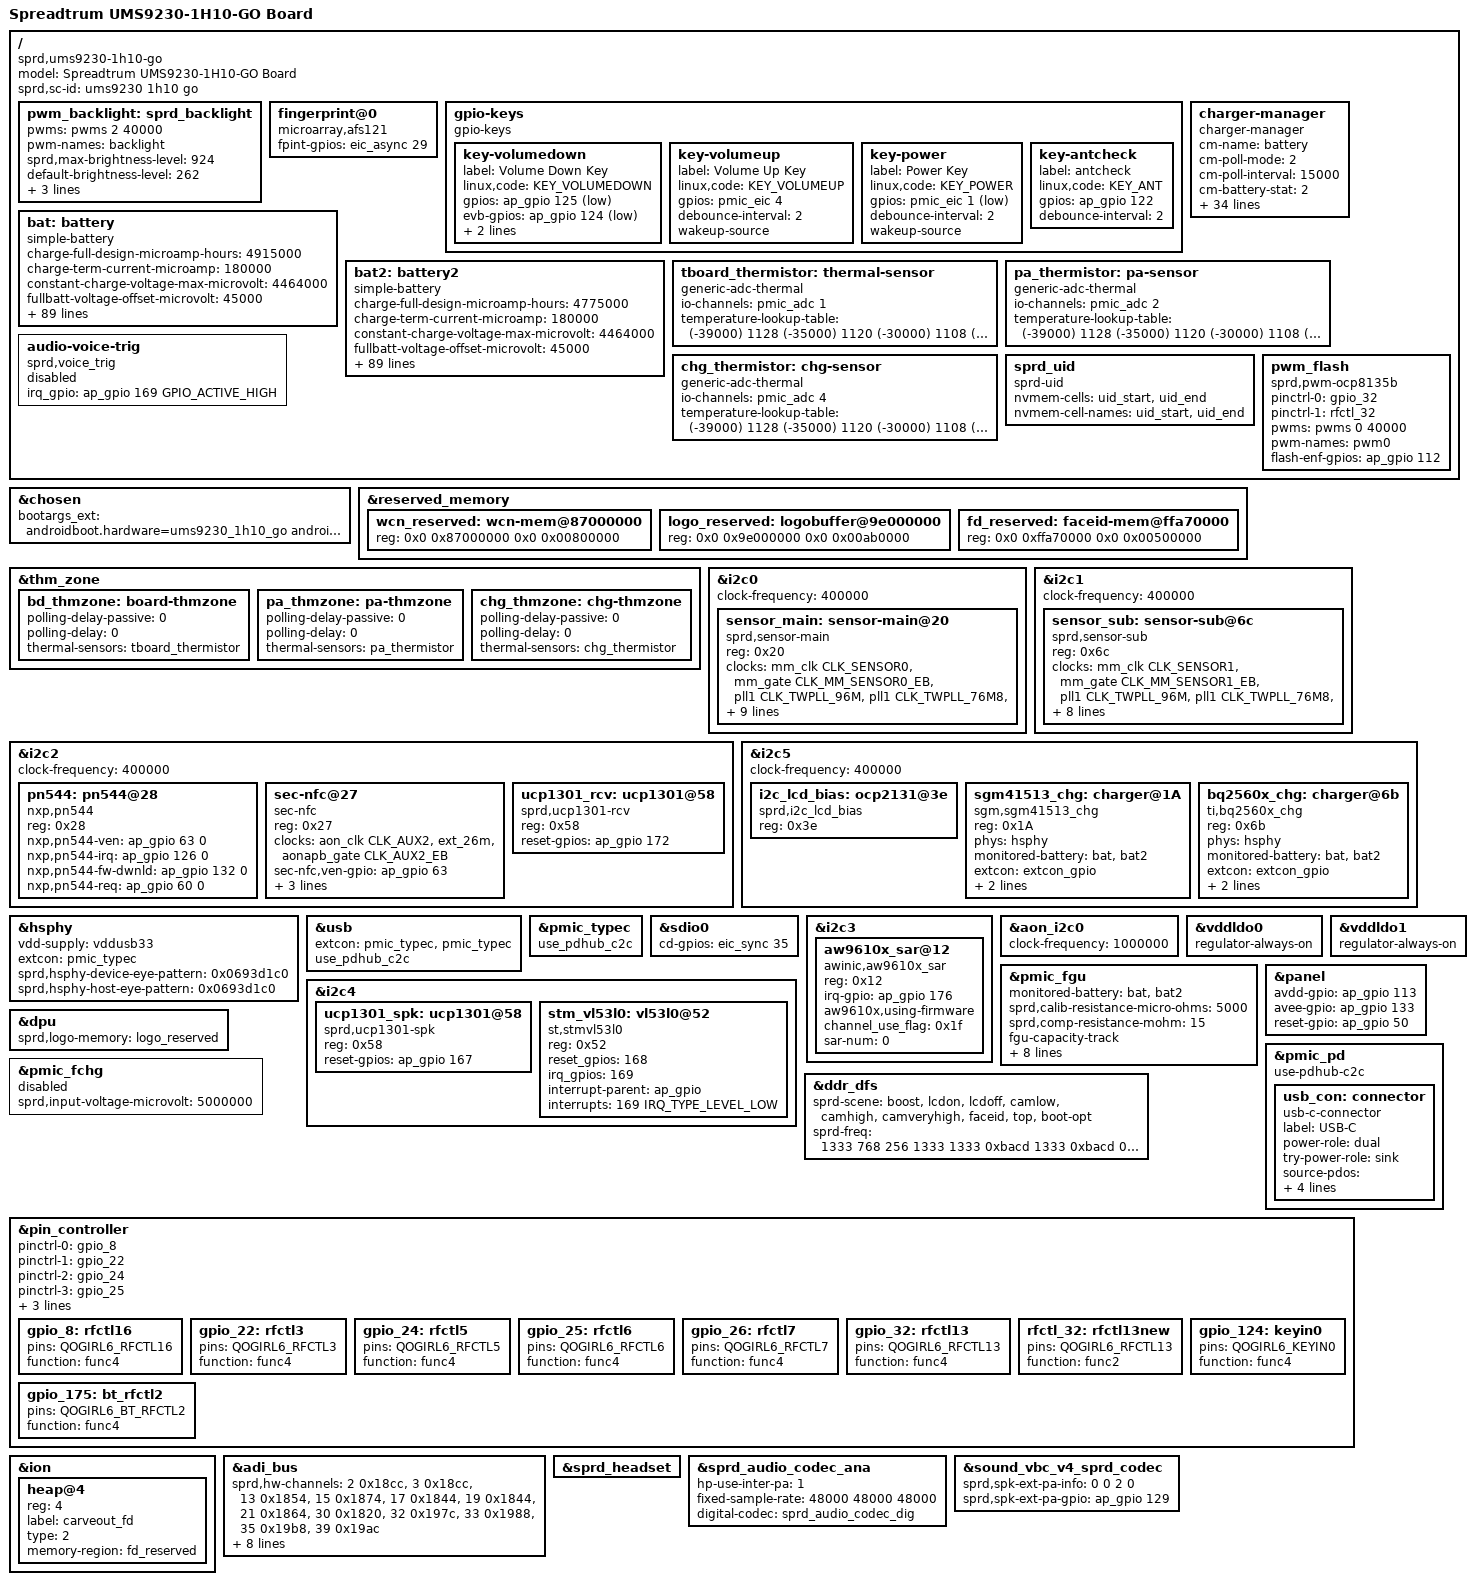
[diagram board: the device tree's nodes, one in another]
/dts-v1/;
/plugin/;
#include <dt-bindings/input/input.h>
#include <dt-bindings/gpio/gpio.h>
#include <dt-bindings/interrupt-controller/arm-gic.h>
#include <dt-bindings/clock/sprd,ums9230-clk.h>
#include <dt-bindings/mfd/sprd,sc2730-regs.h>
#include <dt-bindings/mfd/sprd,sc2730-mask.h>
#include <dt-bindings/usb/pd.h>
#include "lcd/lcd_ili9882q_boe_mipi_hd.dtsi"
#include "lcd/lcd_nt36528_tm_mipi_hd.dtsi"
#include "lcd/lcd_dummy_mipi.dtsi"
#include "tp/ums9230-spi3-gpio144-145-tp.dtsi"
#include "ums9230-wcn.dtsi"

/ {

	model = "Spreadtrum UMS9230-1H10-GO Board";

	compatible = "sprd,ums9230-1h10-go";

	sprd,sc-id = "ums9230 1h10 go";
	fragment {
		target-path = "/";
		__overlay__ {
			pwm_backlight: sprd_backlight {
				//compatible = "sprd,sharkl6-backlight";	//m170 use cabc_pwm, not pwm_backlight
				pwms = <&pwms 2 40000>;
				pwm-names = "backlight";
				sprd,max-brightness-level = <924>;
				default-brightness-level = <262>;
				sprd,brightness-scale = <1023>;
				brightness-levels = <
							  0   3   4   5   6   7
					  8   9  10  11  12  13  14  16  17  18
					 19  20  21  22  23  24  25  26  27  28
					 29  31  33  35  37  39  41  43  45  47
					 48  50  52  54  56  58  60  62  64  67
					 69  72  74  76  78  80  82  84  86  88
					 90  92  94  96  98 100 102 104 107 109
					112 114 116 118 120 122 124 126 128 130
					132 134 136 138 140 142 144 147 149 151
					154 156 158 160 162 164 166 168 170 172
					175 178 181 184 187 190 193 196 199 203
					205 208 211 214 217 220 223 226 229 234
					237 240 243 247 250 253 256 259 263 266
					269 270 274 277 280 283 287 290 294 297
					300 303 307 310 314 318 325 329 334 339
					340 343 347 350 354 358 365 369 374 380
					382 385 389 392 396 400 407 411 416 422
					426 430 434 438 442 446 452 457 460 464
					470 474 480 486 492 498 504 508 512 516
					522 527 532 536 540 545 550 555 561 568
					574 579 584 589 594 600 605 610 615 620
					625 630 635 641 647 652 657 662 667 673
					688 694 700 706 712 716 720 725 730 735
					740 746 752 758 764 770 776 782 790 798
					803 810 817 825 832 840 845 850 855 861
					866 872 878 884 890 896 903 911 918 924
				>;
			};

			fingerprint@0 {
				compatible = "microarray,afs121";
				fpint-gpios = <&eic_async 29 0>;
			};

			gpio-keys {
				compatible = "gpio-keys";

				key-volumedown {
					label = "Volume Down Key";
					linux,code = <KEY_VOLUMEDOWN>;
					gpios = <&ap_gpio 125 GPIO_ACTIVE_LOW>;
					evb-gpios = <&ap_gpio 124 GPIO_ACTIVE_LOW>;
					debounce-interval = <2>;
					wakeup-source;
				};

				key-volumeup {
					label = "Volume Up Key";
					linux,code = <KEY_VOLUMEUP>;
					gpios = <&pmic_eic 4 GPIO_ACTIVE_HIGH>;
					debounce-interval = <2>;
					wakeup-source;
				};

				key-power {
					label = "Power Key";
					linux,code = <KEY_POWER>;
					gpios = <&pmic_eic 1 GPIO_ACTIVE_LOW>;
					debounce-interval = <2>;
					wakeup-source;
				};

				key-antcheck {
					label = "antcheck";
					linux,code = <KEY_ANT>;
					gpios = <&ap_gpio 122 GPIO_ACTIVE_HIGH>;
					debounce-interval = <2>;
					//wakeup-source;
				};

			};

			bat: battery {
				compatible = "simple-battery";
				charge-full-design-microamp-hours = <4915000>;
				charge-term-current-microamp = <180000>;
				constant-charge-voltage-max-microvolt = <4464000>;
				fullbatt-voltage-offset-microvolt = <45000>;
				factory-internal-resistance-micro-ohms = <126000>;
				voltage-min-design-microvolt = <3450000>;
				fast-charge-threshold-microvolt = <4100000>;
				fullbatt-voltage = <4350000>;
				fullbatt-current = <242000>;
				first-fullbatt-current = <150000>;
				fullbatt-track-end-vol = <4295000>;
				fullbatt-track-end-cur = <130000>;
				first-calib-voltage = <3683000>;
				first-calib-capacity = <50>;
				//ir-us-upper-limit-microvolt = <4500000>;
				//ir-cv-offset-microvolt = <100000>;
				//ir-rc-micro-ohms = <20000>;

				ocv-capacity-celsius = <25>;
				ocv-capacity-table-0 = <4389000 100>, <4330000 95>, <4273000 90>,
							<4214000 85>, <4157000 80>, <4103000 75>,
							<4052000 70>, <4006000 65>, <3964000 60>,
							<3905000 55>, <3868000 50>, <3842000 45>,
							<3821000 40>, <3804000 35>, <3789000 30>,
							<3769000 25>, <3748000 20>, <3724000 15>,
							<3694000 10>, <3683000 5>, <3400000 0>;
				voltage-temp-table = <1491668 600>, <1404493 650>, <1307739 700>, <1203814 750>,
							<1095466 800>, <986112 850>, <878559 900>,
							  <775113 950>, <678461 1000>, <590240 1050>,
							  <510773 1100>, <440156 1150>, <378279 1200>,
							  <324561 1250>, <278079 1300>, <238260 1350>,
							  <204267 1400>, <175208 1450>, <150460 1500>,
							  <129410 1550>, <111497 1600>, <96484 1650>,
							<83711 1700>, <72772 1750>, <63423 1800>,
							<55444 1850>, <48599 1900>, <42668 1950>,
							<37552 2000>, <33167 2050>;
				capacity-temp-table = <45 99>, <25 100>, <10 99>, <0 92>, <(-10) 86>;
				resistance-temp-table = <45 83>, <25 100>, <10 155>, <0 929>, <(-10) 994>;

				/*battery-internal-resistance-celsius = <(-20)>, <(-10)>, <0>, <10>,
					<25>, <35>, <45>, <55>;
				battery-internal-resistance-table-0 = <1224>, <1224>, <1140>,
					<1084>, <1034>, <1001>, <994>, <992>, <992>, <992>,
					<996>, <1002>, <1010>, <1024>, <1045>, <1072>, <1180>,
					<1393>, <1756>, <2461>, <4272>;
				battery-internal-resistance-table-1 = <893>, <893>, <818>, <767>,
					<743>, <705>, <685>, <684>, <678>, <675>, <672>, <673>,
					<679>, <691>, <709>, <734>, <765>, <799>, <839>, <899>,
					<1092>;
				battery-internal-resistance-table-2 = <407>, <407>, <402>, <423>,
					<429>, <428>, <409>, <416>, <408>, <395>, <390>, <390>,
					<393>, <398>, <405>, <416>, <431>, <452>, <492>, <585>,
					<730>;
				battery-internal-resistance-table-3 = <381>, <381>, <378>, <371>,
					<366>, <374>, <358>, <364>, <349>, <332>, <327>, <329>,
					<334>, <340>, <350>, <366>, <386>, <417>, <475>, <585>,
					<771>;
				battery-internal-resistance-table-4 = <182>, <182>, <179>, <179>,
					<179>, <181>, <182>, <195>, <194>, <173>, <164>, <164>,
					<167>, <171>, <175>, <174>, <172>, <179>, <187>, <244>,
					<311>;
				battery-internal-resistance-table-5 = <168>, <168>, <175>, <172>,
					<171>, <171>, <173>, <184>, <176>, <153>, <147>, <147>,
					<150>, <153>, <156>, <152>, <149>, <154>, <158>, <206>,
					<255>;
				battery-internal-resistance-table-6 = <123>, <123>, <122>, <122>,
					<123>, <126>, <130>, <138>, <143>, <120>, <115>, <116>,
					<119>, <124>, <129>, <120>, <117>, <119>, <117>, <139>,
					<156>;
				battery-internal-resistance-table-7 = <106>, <106>, <106>, <106>,
					<108>, <110>, <113>, <119>, <128>, <107>, <104>, <105>,
					<108>, <112>, <117>, <107>, <106>, <107>, <105>, <127>,
					<140>;
				battery-internal-resistance-ocv-table = <4339000>, <4276000>,
					<4221000>, <4169000>, <4118000>, <4072000>, <4022000>,
					<3983000>, <3942000>, <3892000>, <3857000>, <3833000>,
					<3813000>, <3797000>, <3783000>, <3766000>, <3746000>,
					<3723000>, <3693000>, <3680000>, <3439000>;*/

				charge-sdp-current-microamp = <500000 500000>;
				charge-dcp-current-microamp = <2500000 3000000>;
				charge-cdp-current-microamp = <1500000 1500000>;
				charge-unknown-current-microamp = <500000 500000>;
				charge-fchg-current-microamp = <3250000 3000000>;
				charge-flash-current-microamp = <5000000 2700000>;
				charge-wl-bpp-current-microamp = <1000000 1000000>;
				charge-wl-epp-current-microamp = <2000000 1000000>;

				cap-calib-energy-density-ocv-table = <3350000 3800000>, <4150000 4464000>;

				dcp-jeita-temp-table = <800 1010 0 4200000>, <1000 1030 1000000 4464000>, <1150 1180 1000000 4464000>,
					<1450 1420 2500000 4464000>, <1600 1570 2500000 4200000>;
				sdp-jeita-temp-table = <800 1010 0 4200000>, <1000 1030 500000 4464000>, <1150 1180 500000 4464000>,
					<1450 1420 500000 4464000>, <1600 1570 500000 4200000>;
				cdp-jeita-temp-table = <800 1010 0 4200000>, <1000 1030 700000 4464000>, <1150 1180 700000 4464000>,
					<1450 1420 1500000 4464000>, <1600 1570 1500000 4200000>;
				unknown-jeita-temp-table = <800 1010 0 4200000>, <1000 1030 500000 4464000>, <1150 1180 500000 4464000>,
					<1450 1420 500000 4464000>, <1600 1570 500000 4200000>;
				fchg-jeita-temp-table = <1000 1030 0 4200000>, <1150 1180 700000 4464000>,
					<1450 1420 3250000 4464000>, <1600 1570 700000 4200000>;
				flash-jeita-temp-table = <1000 1020 0 4464000>, <1050 1070 500000 4464000>,
					<1120 1140 1000000 4464000>, <1160 1180 1500000 4464000>,
					<1220 1240 4500000 4464000>, <1340 1360 5000000 4464000>,
					<1370 1350 5000000 4464000>, <1400 1380 4500000 4464000>,
					<1420 1400 4250000 4464000>, <1450 1430 4000000 4464000>,
					<1600 1570 1000000 4420000>;
				wl-bpp-jeita-temp-table = <1000 1030 0 4464000>, <1150 1180 500000 4464000>,
					<1450 1420 1000000 4464000>, <1600 1570 5000000 4200000>;
				wl-epp-jeita-temp-table = <1000 1030 0 4464000>, <1150 1180 500000 4464000>,
					<1450 1420 2000000 4464000>, <1600 1570 500000 4200000>;
				force-jeita-status = <2>;
			};

				bat2: battery2 {
				compatible = "simple-battery";
				charge-full-design-microamp-hours = <4775000>;
				charge-term-current-microamp = <180000>;
				constant-charge-voltage-max-microvolt = <4464000>;
				fullbatt-voltage-offset-microvolt = <45000>;
				factory-internal-resistance-micro-ohms = <120000>;
				voltage-min-design-microvolt = <3450000>;
				fast-charge-threshold-microvolt = <4100000>;
				fullbatt-voltage = <4350000>;
				fullbatt-current = <242000>;
				first-fullbatt-current = <150000>;
				fullbatt-track-end-vol = <4295000>;
				fullbatt-track-end-cur = <130000>;
				first-calib-voltage = <3682000>;
				first-calib-capacity = <50>;
				//ir-us-upper-limit-microvolt = <4500000>;
				//ir-cv-offset-microvolt = <100000>;
				//ir-rc-micro-ohms = <20000>;

				ocv-capacity-celsius = <25>;
				ocv-capacity-table-0 = <4389000 100>, <4340000 95>, <4286000 90>,
							<4229000 85>, <4173000 80>, <4119000 75>,
							<4069000 70>, <4022000 65>, <3974000 60>,
							<3914000 55>, <3881000 50>, <3854000 45>,
							<3832000 40>, <3814000 35>, <3797000 30>,
							<3773000 25>, <3750000 20>, <3723000 15>,
							<3697000 10>, <3682000 5>, <3400000 0>;
				voltage-temp-table = <1491668 600>, <1404493 650>, <1307739 700>, <1203814 750>,
							<1095466 800>, <986112 850>, <878559 900>,
							  <775113 950>, <678461 1000>, <590240 1050>,
							  <510773 1100>, <440156 1150>, <378279 1200>,
							  <324561 1250>, <278079 1300>, <238260 1350>,
							  <204267 1400>, <175208 1450>, <150460 1500>,
							  <129410 1550>, <111497 1600>, <96484 1650>,
							<83711 1700>, <72772 1750>, <63423 1800>,
                                                        <55444 1850>, <48599 1900>, <42668 1950>,
                                                        <37552 2000>, <33167 2050>;
				capacity-temp-table = <45 99>, <25 100>, <10 99>, <0 94>, <(-10) 88>, <(-20) 71>;
				resistance-temp-table = <45 85>, <25 100>, <10 142>, <0 922>, <(-10) 1022>, <(-20) 1170>;

				/*battery-internal-resistance-celsius = <(-20)>, <(-10)>, <0>, <10>,
					<25>, <35>, <45>, <55>;
				battery-internal-resistance-table-0 = <1224>, <1224>, <1140>,
					<1084>, <1034>, <1001>, <994>, <992>, <992>, <992>,
					<996>, <1002>, <1010>, <1024>, <1045>, <1072>, <1180>,
					<1393>, <1756>, <2461>, <4272>;
				battery-internal-resistance-table-1 = <893>, <893>, <818>, <767>,
					<743>, <705>, <685>, <684>, <678>, <675>, <672>, <673>,
					<679>, <691>, <709>, <734>, <765>, <799>, <839>, <899>,
					<1092>;
				battery-internal-resistance-table-2 = <407>, <407>, <402>, <423>,
					<429>, <428>, <409>, <416>, <408>, <395>, <390>, <390>,
					<393>, <398>, <405>, <416>, <431>, <452>, <492>, <585>,
					<730>;
				battery-internal-resistance-table-3 = <381>, <381>, <378>, <371>,
					<366>, <374>, <358>, <364>, <349>, <332>, <327>, <329>,
					<334>, <340>, <350>, <366>, <386>, <417>, <475>, <585>,
					<771>;
				battery-internal-resistance-table-4 = <182>, <182>, <179>, <179>,
					<179>, <181>, <182>, <195>, <194>, <173>, <164>, <164>,
					<167>, <171>, <175>, <174>, <172>, <179>, <187>, <244>,
					<311>;
				battery-internal-resistance-table-5 = <168>, <168>, <175>, <172>,
					<171>, <171>, <173>, <184>, <176>, <153>, <147>, <147>,
					<150>, <153>, <156>, <152>, <149>, <154>, <158>, <206>,
					<255>;
				battery-internal-resistance-table-6 = <123>, <123>, <122>, <122>,
					<123>, <126>, <130>, <138>, <143>, <120>, <115>, <116>,
					<119>, <124>, <129>, <120>, <117>, <119>, <117>, <139>,
					<156>;
				battery-internal-resistance-table-7 = <106>, <106>, <106>, <106>,
					<108>, <110>, <113>, <119>, <128>, <107>, <104>, <105>,
					<108>, <112>, <117>, <107>, <106>, <107>, <105>, <127>,
					<140>;
				battery-internal-resistance-ocv-table = <4339000>, <4276000>,
					<4221000>, <4169000>, <4118000>, <4072000>, <4022000>,
					<3983000>, <3942000>, <3892000>, <3857000>, <3833000>,
					<3813000>, <3797000>, <3783000>, <3766000>, <3746000>,
					<3723000>, <3693000>, <3680000>, <3439000>;*/

				charge-sdp-current-microamp = <500000 500000>;
				charge-dcp-current-microamp = <2500000 3000000>;
				charge-cdp-current-microamp = <1500000 1500000>;
				charge-unknown-current-microamp = <500000 500000>;
				charge-fchg-current-microamp = <3250000 3000000>;
				charge-flash-current-microamp = <5000000 2700000>;
				charge-wl-bpp-current-microamp = <1000000 1000000>;
				charge-wl-epp-current-microamp = <2000000 1000000>;

				cap-calib-energy-density-ocv-table = <3350000 3800000>, <4150000 4464000>;

				dcp-jeita-temp-table = <800 1010 0 4200000>, <1000 1030 1000000 4464000>, <1150 1180 1000000 4464000>,
					<1450 1420 2500000 4464000>, <1600 1570 2500000 4200000>;
				sdp-jeita-temp-table = <800 1010 0 4200000>, <1000 1030 500000 4464000>, <1150 1180 500000 4464000>,
					<1450 1420 500000 4464000>, <1600 1570 500000 4200000>;
				cdp-jeita-temp-table = <800 1010 0 4200000>, <1000 1030 700000 4464000>, <1150 1180 700000 4464000>,
					<1450 1420 1500000 4464000>, <1600 1570 1500000 4200000>;
				unknown-jeita-temp-table = <800 1010 0 4200000>, <1000 1030 500000 4464000>, <1150 1180 500000 4464000>,
					<1450 1420 500000 4464000>, <1600 1570 500000 4200000>;
				fchg-jeita-temp-table = <1000 1030 0 4464000>, <1150 1180 700000 4464000>,
					<1450 1420 3250000 4464000>, <1600 1570 700000 4200000>;
				flash-jeita-temp-table = <1000 1020 0 4464000>, <1050 1070 500000 4380000>,
					<1120 1140 1000000 4464000>, <1160 1180 1500000 4464000>,
					<1220 1240 4500000 4464000>, <1340 1360 5000000 4464000>,
					<1370 1350 5000000 4464000>, <1400 1380 4500000 4464000>,
					<1420 1400 4250000 4464000>, <1450 1430 4000000 4464000>,
					<1600 1570 1000000 4200000>;
				wl-bpp-jeita-temp-table = <1000 1030 0 4464000>, <1150 1180 500000 4464000>,
					<1450 1420 1000000 4464000>, <1600 1570 5000000 4200000>;
				wl-epp-jeita-temp-table = <1000 1030 0 4464000>, <1150 1180 500000 4464000>,
					<1450 1420 2000000 4464000>, <1600 1570 500000 4200000>;
				force-jeita-status = <2>;
			};

			charger-manager {
				compatible = "charger-manager";
				cm-name = "battery";
				cm-poll-mode = <2>;
				cm-poll-interval = <15000>;
				cm-battery-stat = <2>;

				cm-fullbatt-vchkdrop-ms = <30000>;
				cm-fullbatt-vchkdrop-volt = <60000>;
				cm-fullbatt-capacity = <100>;
				/*Charge pump target charge current*/
				cm-cp-taper-current = <1000000>;

				/* M170 code for sgm41513 by liuyansheng10 at 220828 begin */
				cm-chargers = "charger";
				//cm-charge-pumps = "bq2597x-standalone";
				//cm-wireless-chargers = "nu1619_wireless_charger";
				//cm-wireless-charge-pump-converters = "hl1506_cp_converter";
				/* M170 code for sgm41513 by liuyansheng10 at 220828 end */
				cm-fuel-gauge = "sc27xx-fgu";

				/* in deci centigrade */
				cm-battery-cold = <200>;
				cm-battery-cold-in-minus;
				cm-battery-hot = <800>;
				cm-battery-temp-diff = <100>;

				/* Allow charging for 6hr */
				cm-charging-max = <72000000>;
				/* recovery charging after stop charging 45min */
				cm-discharging-max = <2700000>;

				/* the interval to feed charger watchdog */
				cm-wdt-interval = <60>;

				/* drop voltage in microVolts to allow shutdown */
				cm-shutdown-voltage = <3380000>;

				/* when 99% of the time is exceeded, it will be forced to 100% */
				cm-tickle-time-out = <200>;

				/* how much time to allow capacity change */
				cm-one-cap-time = <30>;
				cm-thermal-zone = "board-thmzone";
				/* when the safe charging voltage is exceeded, stop charging */
				cm-charge-voltage-max = <6500000>;
				cm-fast-charge-voltage-max = <10500000>;
				cm-flash-charge-voltage-max = <12000000>;
				cm-wireless-charge-voltage-max = <6500000>;
				cm-wireless-fast-charge-voltage-max = <12000000>;
				/* drop voltage in microVolts to restart charging */
				cm-charge-voltage-drop = <700000>;
				cm-fast-charge-voltage-drop = <700000>;
				cm-flash-charge-voltage-drop = <1000000>;
				cm-wireless-charge-voltage-drop = <700000>;
				cm-wireless-fast-charge-voltage-drop = <1000000>;

				/* sprd_fchg parameter */
				//sprd,support-fchg;
				//sprd,support-pd-pps;
				sprd,pd-fixed-max-microwatt = <10000000>;

				//cm-cap-remap-table = <1 2 3>, <2 3 2>, <98 99 2>, <99 100 3>;

				monitored-battery = <&bat &bat2>;
				cm-keep-awake;

				phys = <&hsphy>;
				extcon = <&pmic_typec>, <&pmic_pd>;
				pd-extcon-enable;
				use-typec-extcon;

			};

			tboard_thermistor: thermal-sensor {
				compatible = "generic-adc-thermal";
				#thermal-sensor-cells = <0>;
				io-channels = <&pmic_adc 1>;
				io-channel-names = "sensor-channel";
				temperature-lookup-table = <
					(-39000) 1128
					(-35000) 1120
					(-30000) 1108
					(-28000) 1103
					(-26000) 1097
					(-24000) 1089
					(-22000) 1082
					(-20000) 1073
					(-18000) 1064
					(-16000) 1054
					(-14000) 1043
					(-12000) 1032
					(-10000) 1019
					(-9000) 1012
					(-8000) 1005
					(-7000) 998
					(-6000) 990
					(-5000) 983
					(-4000) 975
					(-3000) 966
					(-2000) 957
					(-1000) 949
					0000 940
					1000 931
					2000 921
					3000 912
					4000 902
					5000 891
					6000 881
					7000 870
					8000 855
					9000 845
					10000 834
					11000 823
					12000 811
					13000 799
					14000 788
					15000 776
					16000 764
					17000 751
					18000 740
					19000 727
					20000 715
					21000 704
					22000 692
					23000 679
					24000 665
					25000 652
					26000 639
					27000 626
					28000 614
					29000 601
					30000 589
					31000 577
					32000 564
					33000 552
					34000 539
					35000 527
					36000 515
					37000 503
					38000 491
					39000 480
					40000 468
					41000 457
					42000 446
					43000 518
					44000 423
					45000 412
					46000 401
					47000 391
					48000 381
					49000 371
					50000 361
					51000 351
					52000 342
					53000 333
					54000 324
					55000 315
					56000 306
					57000 297
					58000 289
					59000 281
					60000 273
					61000 265
					62000 258
					63000 251
					64000 243
					65000 237
					66000 230
					67000 223
					68000 217
					69000 211
					70000 205
					74000 182
					78000 162
					82000 144
					86000 128
					90000 114
					94000 102
					98000 91
					102000 81
					106000 72
					110000 65
					114000 58
					118000 52
					122000 47
					125000 43 >;
			};

			pa_thermistor: pa-sensor {
				compatible = "generic-adc-thermal";
				#thermal-sensor-cells = <0>;
				io-channels = <&pmic_adc 2>;
				io-channel-names = "sensor-channel";
				temperature-lookup-table = <
					(-39000) 1128
					(-35000) 1120
					(-30000) 1108
					(-28000) 1103
					(-26000) 1097
					(-24000) 1089
					(-22000) 1082
					(-20000) 1073
					(-18000) 1064
					(-16000) 1054
					(-14000) 1043
					(-12000) 1032
					(-10000) 1019
					(-9000) 1012
					(-8000) 1005
					(-7000) 998
					(-6000) 990
					(-5000) 983
					(-4000) 975
					(-3000) 966
					(-2000) 957
					(-1000) 949
					0000 940
					1000 931
					2000 921
					3000 912
					4000 902
					5000 891
					6000 881
					7000 870
					8000 855
					9000 845
					10000 834
					11000 823
					12000 811
					13000 799
					14000 788
					15000 776
					16000 764
					17000 751
					18000 740
					19000 727
					20000 715
					21000 704
					22000 692
					23000 679
					24000 665
					25000 652
					26000 639
					27000 626
					28000 614
					29000 601
					30000 589
					31000 577
					32000 564
					33000 552
					34000 539
					35000 527
					36000 515
					37000 503
					38000 491
					39000 480
					40000 468
					41000 457
					42000 446
					43000 518
					44000 423
					45000 412
					46000 401
					47000 391
					48000 381
					49000 371
					50000 361
					51000 351
					52000 342
					53000 333
					54000 324
					55000 315
					56000 306
					57000 297
					58000 289
					59000 281
					60000 273
					61000 265
					62000 258
					63000 251
					64000 243
					65000 237
					66000 230
					67000 223
					68000 217
					69000 211
					70000 205
					74000 182
					78000 162
					82000 144
					86000 128
					90000 114
					94000 102
					98000 91
					102000 81
					106000 72
					110000 65
					114000 58
					118000 52
					122000 47
					125000 43 >;
			};

			chg_thermistor: chg-sensor {
				compatible = "generic-adc-thermal";
				#thermal-sensor-cells = <0>;
				io-channels = <&pmic_adc 4>;
				io-channel-names = "sensor-channel";
				temperature-lookup-table = <
					(-39000) 1128
					(-35000) 1120
					(-30000) 1108
					(-28000) 1103
					(-26000) 1097
					(-24000) 1089
					(-22000) 1082
					(-20000) 1073
					(-18000) 1064
					(-16000) 1054
					(-14000) 1043
					(-12000) 1032
					(-10000) 1019
					(-9000) 1012
					(-8000) 1005
					(-7000) 998
					(-6000) 990
					(-5000) 983
					(-4000) 975
					(-3000) 966
					(-2000) 957
					(-1000) 949
					0000 940
					1000 931
					2000 921
					3000 912
					4000 902
					5000 891
					6000 881
					7000 870
					8000 855
					9000 845
					10000 834
					11000 823
					12000 811
					13000 799
					14000 788
					15000 776
					16000 764
					17000 751
					18000 740
					19000 727
					20000 715
					21000 704
					22000 692
					23000 679
					24000 665
					25000 652
					26000 639
					27000 626
					28000 614
					29000 601
					30000 589
					31000 577
					32000 564
					33000 552
					34000 539
					35000 527
					36000 515
					37000 503
					38000 491
					39000 480
					40000 468
					41000 457
					42000 446
					43000 518
					44000 423
					45000 412
					46000 401
					47000 391
					48000 381
					49000 371
					50000 361
					51000 351
					52000 342
					53000 333
					54000 324
					55000 315
					56000 306
					57000 297
					58000 289
					59000 281
					60000 273
					61000 265
					62000 258
					63000 251
					64000 243
					65000 237
					66000 230
					67000 223
					68000 217
					69000 211
					70000 205
					74000 182
					78000 162
					82000 144
					86000 128
					90000 114
					94000 102
					98000 91
					102000 81
					106000 72
					110000 65
					114000 58
					118000 52
					122000 47
					125000 43 >;
			};

			audio-voice-trig {
				status = "disable";
				compatible = "sprd,voice_trig";
				irq_gpio = <&ap_gpio 169 GPIO_ACTIVE_HIGH>;
			};

			sprd_uid {
				compatible = "sprd-uid";
				nvmem-cells = <&uid_start>, <&uid_end>;
				nvmem-cell-names = "uid_start", "uid_end";
			};

			pwm_flash: pwm_flash {
				compatible = "sprd,pwm-ocp8135b";
				pinctrl-names = "gpio_32","rfctl_32";
				pinctrl-0 = <&gpio_32>;
				pinctrl-1 = <&rfctl_32>;
				pwms = <&pwms 0 40000>;
				pwm-names = "pwm0";
				flash-enf-gpios = <&ap_gpio 112 0>;
				#pwm-cells = <2>;
			};
		};
	};
};

&chosen {
	bootargs_ext = "androidboot.hardware=ums9230_1h10_go androidboot.dtbo_idx=0";
};

&reserved_memory {
	#address-cells = <2>;
	#size-cells = <2>;
	wcn_reserved: wcn-mem@87000000 {
		reg = <0x0 0x87000000 0x0 0x00800000>;
	};

	logo_reserved: logobuffer@9e000000{
		reg = <0x0 0x9e000000 0x0 0x00ab0000>;
	};

	fd_reserved: faceid-mem@ffa70000 {
		reg = <0x0 0xffa70000 0x0 0x00500000>;
	};
};

&thm_zone {
	bd_thmzone: board-thmzone {
		polling-delay-passive = <0>;
		polling-delay = <0>;
		thermal-sensors = <&tboard_thermistor>;
	};

	pa_thmzone: pa-thmzone {
		polling-delay-passive = <0>;
		polling-delay = <0>;
		thermal-sensors = <&pa_thermistor>;
	};

	chg_thmzone: chg-thmzone {
		polling-delay-passive = <0>;
		polling-delay = <0>;
		thermal-sensors = <&chg_thermistor>;
	};
};

&i2c0 {
	status = "okay";
	clock-frequency = <400000>;
	#address-cells = <1>;
	#size-cells = <0>;

	sensor_main: sensor-main@20 {
		compatible = "sprd,sensor-main";
		reg = <0x20>;
		clock-names = "clk_src","sensor_eb",
			"clk_96m","clk_76m8",
			"clk_48m","clk_26m";
		clocks = <&mm_clk CLK_SENSOR0>,<&mm_gate CLK_MM_SENSOR0_EB>,
				<&pll1 CLK_TWPLL_96M>,<&pll1 CLK_TWPLL_76M8>,
				<&pll1 CLK_TWPLL_48M>,<&ext_26m>;
		vddio-supply = <&vddcamio>;
		vddcama-supply = <&vddcama0>;
		vddcamd-supply = <&vddcamd0>;
		vddcammot-supply = <&vddcammot>;
		reset-gpios = <&ap_gpio 44 0>;
	/*	power-down-gpios = <&ap_gpio 47 0>; */
		sprd,phyid = <2>;
		csi = <&csi0>;
		power-domains = <&mm_domain>;
	};
/*
	sensor_sub: sensor-sub@5a {
		compatible = "sprd,sensor-sub";
		reg = <0x5a>;
		clock-names = "clk_src","sensor_eb",
			"clk_96m","clk_76m8",
			"clk_48m","clk_26m";
		clocks = <&mm_clk CLK_SENSOR0>,<&mm_gate CLK_MM_SENSOR0_EB>,
				<&pll1 CLK_TWPLL_96M>,<&pll1 CLK_TWPLL_76M8>,
				<&pll1 CLK_TWPLL_48M>,<&ext_26m>;
		vddio-supply = <&vddcamio>;
		vddcama-supply = <&vddcama0>;
		dvdd-gpios = <&ap_gpio 11 0>;
		vddcammot-supply = <&vddcammot>;
		reset-gpios = <&ap_gpio 44 0>;
		power-down-gpios = <&ap_gpio 46 0>;
		mipi-switch-en-gpios = <&ap_gpio 55 0>;
		mipi-switch-mode-gpios = <&ap_gpio 8 0>;
		sprd,phyid = <2>;
		csi = <&csi0>;
		power-domains = <&mm_domain>;
	};
*/
};

&i2c1 {
	status = "okay";
	clock-frequency = <400000>;
	#address-cells = <1>;
	#size-cells = <0>;

	sensor_sub: sensor-sub@6c {
		compatible = "sprd,sensor-sub";
		reg = <0x6c>;
		clock-names = "clk_src","sensor_eb",
			"clk_96m","clk_76m8",
			"clk_48m","clk_26m";
		clocks = <&mm_clk CLK_SENSOR1>,<&mm_gate CLK_MM_SENSOR1_EB>,
				<&pll1 CLK_TWPLL_96M>,<&pll1 CLK_TWPLL_76M8>,
				<&pll1 CLK_TWPLL_48M>,<&ext_26m>;
		vddio-supply = <&vddcamio>;
		vddcama-supply = <&vddcama1>;
		vddcamd-supply = <&vddcamd1>;
	/*	vddcammot-supply = <&vddcammot>;*/
	/*	avdd-gpios = <&ap_gpio 33 0>;*/
	/*	mot-gpios = <&ap_gpio 88 0>;*/
		reset-gpios = <&ap_gpio 45 0>;
	/*	power-down-gpios = <&ap_gpio 40 0>;*/
	/*	mipi-switch-en-gpios = <&ap_gpio 55 0>;*/
	/*	mipi-switch-mode-gpios = <&ap_gpio 8 0>;*/
		sprd,phyid = <0>;
		csi = <&csi0>;
		power-domains = <&mm_domain>;
	};


};

&i2c2{
	status = "okay";
	clock-frequency = <400000>;
	#address-cells = <1>;
	#size-cells = <0>;
	pn544:pn544@28{
		compatible = "nxp,pn544";
		reg = <0x28>;
		//clock-names = "nfc_clk","source","enable";
		//clocks = <&aon_clk CLK_AUX2>,<&ext_26m>,<&aonapb_gate CLK_AUX2_EB>;
		nxp,pn544-ven = <&ap_gpio 63 0>;
		nxp,pn544-irq = <&ap_gpio 126 0>;
		nxp,pn544-fw-dwnld = <&ap_gpio 132 0>;
		nxp,pn544-req = <&ap_gpio 60 0>;
		status = "okay";
	};
};

&i2c5 {
	status = "okay";
	clock-frequency = <400000>;
	#address-cells = <1>;
	#size-cells = <0>;

	i2c_lcd_bias: ocp2131@3e {
		compatible = "sprd,i2c_lcd_bias";
		reg = <0x3e>;
		status = "okay";
	};

	sgm41513_chg: charger@1A {
                compatible = "sgm,sgm41513_chg";
                reg = <0x1A>;
		phys = <&hsphy>;
                monitored-battery = <&bat &bat2>;
		extcon = <&extcon_gpio>;
                irq-gpio = <&ap_gpio 115 GPIO_ACTIVE_LOW>;
		use-typec-extcon;
/*
		vddvbus:otg-vbus {
			regulator-name = "vddvbus";
		};
*/
        };

	bq2560x_chg: charger@6b {
		compatible = "ti,bq2560x_chg";
		reg = <0x6b>;
		phys = <&hsphy>;
		monitored-battery = <&bat &bat2>;
		extcon = <&extcon_gpio>;
		irq-gpio = <&ap_gpio 115 GPIO_ACTIVE_LOW>;
		use-typec-extcon;
/*
		vddvbus1:otg-vbus {
			regulator-name = "vddvbus1";
		};
*/
	};
/*

	bq2597x_chg: charger@65 {
		compatible = "ti,bq2597x-standalone";
		reg = <0x65>;
		irq-gpio = <&ap_gpio 126 GPIO_ACTIVE_LOW>;

		ti,bq2597x,bus-therm-disable = <1>;
		ti,bq2597x,regulation-disable = <1>;

		ti,bq2597x,bat-ovp-threshold = <4400>;
		ti,bq2597x,bat-ovp-alarm-threshold = <4340>;
		ti,bq2597x,bat-ocp-threshold = <5500>;
		ti,bq2597x,bat-ocp-alarm-threshold = <5000>;
		ti,bq2597x,bus-ovp-threshold = <11500>;
		ti,bq2597x,bus-ovp-alarm-threshold = <10500>;
		ti,bq2597x,bus-ocp-threshold = <3000>;
		ti,bq2597x,bus-ocp-alarm-threshold = <2700>;
		ti,bq2597x,bat-ucp-alarm-threshold = <1000>;
		ti,bq2597x,bat-therm-threshold = <0x15>;
		ti,bq2597x,bus-therm-threshold = <0x15>;
		ti,bq2597x,die-therm-threshold = <0xc8>;
		ti,bq2597x,ac-ovp-threshold = <13>;
		ti,bq2597x,sense-resistor-mohm = <5>;
		ti,bq2597x,adc-sample-bits = <13>;
		ti,bq2597x,ibat-regulation-threshold = <300>;
		ti,bq2597x,vbat-regulation-threshold = <100>;
		ti,bq2597x,vdrop-threshold = <400>;
		ti,bq2597x,vdrop-deglitch = <5000>;
		ti,bq2597x,ss-timeout = <100000>;
		ti,bq2597x,watchdog-timer = <30000>;
	};

	hl1506_cp_converter: charger@1b {
		compatible = "halo,hl1506_cp_converter";
		reg = <0x1b>;
		chg_pump_en_gpio = <&ap_gpio 147 GPIO_ACTIVE_HIGH>;
	};

	nu1619_rx: charger@61 {
		compatible = "nuvolta,wl_charger_nu1619";
		reg = <0x61>;
		phys = <&hsphy>;
		rx,irq_gpio = <&ap_gpio 146 GPIO_ACTIVE_LOW>;
		switch_chg_en_gpio = <&ap_gpio 171 GPIO_ACTIVE_HIGH>;
		switch_flag_en_gpio = <&ap_gpio 176 GPIO_ACTIVE_HIGH>;
	};
*/
/* M170 code for sgm41513 by liuyansheng10 at 220828 end */
/*
	flash_ic: flash-ic@63 {
		compatible = "sprd,flash-ocp8137";
		reg = <0x63>;
		sprd,flash-ic = <8137>;
		sprd,torch = <1>;
		sprd,preflash = <1>;
		sprd,highlight = <1>;
		sprd,torch-level = <128>;
		sprd,preflash-level = <128>;
		sprd,highlight-level = <128>;
		sprd,lvfm-enable = <1>;
		flash-torch-en-gpios = <&ap_gpio 32 0>;
		flash-chip-en-gpios = <&ap_gpio 138 0>;
		flash-en-gpios = <&ap_gpio 139 0>;
		flash-sync-gpios = <&ap_gpio 121 0>;
	};
*/
};

/*
&i2c6 {
	status = "okay";
	clock-frequency = <400000>;
	#address-cells = <1>;
	#size-cells = <0>;

	sensor_sub2: sensor-sub2@6e {
		compatible = "sprd,sensor-sub2";
		reg = <0x6e>;
		clock-names = "clk_src","sensor_eb",
			"clk_96m","clk_76m8",
			"clk_48m","clk_26m";
		clocks = <&mm_clk CLK_SENSOR2>,<&mm_gate CLK_MM_SENSOR2_EB>,
			<&pll1 CLK_TWPLL_96M>,<&pll1 CLK_TWPLL_76M8>,
			<&pll1 CLK_TWPLL_48M>,<&ext_26m>;
		vddio-supply = <&vddcamio>;
		avdd-gpios = <&ap_gpio 130 0>;
		vddcamd-supply = <&vddcamd1>;
		vddcammot-supply = <&vddcammot>;
		mot-gpios = <&ap_gpio 112 0>;
		reset-gpios = <&ap_gpio 114 0>;
		power-down-gpios = <&ap_gpio 40 0>;
		sprd,phyid = <3>;
		csi = <&csi2>;
	};
};
*/

&hsphy {
	vdd-supply = <&vddusb33>;
	extcon = <&pmic_typec>;
	sprd,hsphy-device-eye-pattern = <0x0693d1c0>;
	sprd,hsphy-host-eye-pattern = <0x0693d1c0>;
	status = "okay";
};

&usb {
	extcon = <&pmic_typec>, <&pmic_typec>;
	//vbus-supply = <&vddvbus>;
	//vbus1-supply = <&vddvbus1>;
	status = "okay";
	use_pdhub_c2c;
};

&pmic_typec {
	use_pdhub_c2c;
 };

&sdio0 {
	cd-gpios = <&eic_sync 35 GPIO_ACTIVE_HIGH>;
};

&i2c2 {
	status = "okay";
	#address-cells = <1>;
	#size-cells = <0>;
	sec-nfc@27 {
		compatible = "sec-nfc";
		reg = <0x27>;
		clock-names = "nfc_clk","source","enable";
		clocks = <&aon_clk CLK_AUX2>, <&ext_26m>, <&aonapb_gate CLK_AUX2_EB>;
		sec-nfc,ven-gpio = <&ap_gpio 63 0>;
		sec-nfc,firm-gpio = <&ap_gpio 61 0>;
		sec-nfc,irq-gpio = <&ap_gpio 62 0>;
		sec-nfc,clk-req = <&ap_gpio 60 0>;
	};

	ucp1301_rcv: ucp1301@58 {
		compatible = "sprd,ucp1301-rcv";
		reg = <0x58>;
		reset-gpios = <&ap_gpio 172 GPIO_ACTIVE_HIGH>;
		#sound-dai-cells = <1>;
	};
};

&i2c3 {
	status = "okay";
	#address-cells = <1>;
	#size-cells = <0>;

	aw9610x_sar@12 {
		compatible = "awinic,aw9610x_sar";
		reg = <0x12>;
		//reset-gpio = <&ap_gpio 63 0>;
		irq-gpio = <&ap_gpio 176 0>;
		aw9610x,using-firmware;
		//vcc0-supply = <&pm660l_l4>;
		channel_use_flag = <0x1f>;
		sar-num = <0>;
		status = "okay";
	};
};

&i2c4 {
	status = "okay";
	#address-cells = <1>;
	#size-cells = <0>;
	ucp1301_spk: ucp1301@58 {
		compatible = "sprd,ucp1301-spk";
		reg = <0x58>;
		reset-gpios = <&ap_gpio 167 GPIO_ACTIVE_HIGH>;
		#sound-dai-cells = <1>;
	};

	stm_vl53l0: vl53l0@52 {
		compatible = "st,stmvl53l0";
		reg = <0x52>;
		reset_gpios = <168>;
		irq_gpios = <169>;
		interrupt-parent = <&ap_gpio>;
		interrupts = <169 IRQ_TYPE_LEVEL_LOW>;
	};
};

&aon_i2c0 {
	status = "okay";
	clock-frequency = <1000000>;
};

&vddldo0 {
	regulator-always-on;
};

&vddldo1 {
	regulator-always-on;
};
&pmic_fgu {
	monitored-battery = <&bat &bat2>;
	sprd,calib-resistance-micro-ohms = <5000>;
	sprd,comp-resistance-mohm = <15>;

	fgu-capacity-track;
	phys = <&hsphy>;

	sprd,relax-counter-threshold = <580>;
	sprd,relax-current-threshold = <30>;
	sprd,capacity-sleep-calibration;

	sprd,capacity-boot-calibration;
	sprd,capacity-charge-cycle;
	sprd,basp;
	use-pdhub-c2c;

};

&panel {
	//sprd,backlight = <&pwm_backlight>;
	avdd-gpio = <&ap_gpio 113 GPIO_ACTIVE_HIGH>;
	avee-gpio = <&ap_gpio 133 GPIO_ACTIVE_HIGH>;
	reset-gpio = <&ap_gpio 50 GPIO_ACTIVE_HIGH>;
};

&dpu {
	sprd,logo-memory = <&logo_reserved>;

	//sprd,backlight = <&pwm_backlight>;
};


&pmic_fchg {
	status = "disable";
	sprd,input-voltage-microvolt = <5000000>;
};

&pmic_pd {
	status = "okay";
	use-pdhub-c2c;
	usb_con: connector {
		compatible = "usb-c-connector";
		label = "USB-C";
		power-role = "dual";
		try-power-role = "sink";
		source-pdos = <PDO_FIXED(5000, 400, PDO_FIXED_USB_COMM |PDO_FIXED_DUAL_ROLE | PDO_FIXED_DATA_SWAP)>;
		sink-pdos = <PDO_FIXED(5000, 3000, PDO_FIXED_USB_COMM)>;
		op-sink-microwatt = <10000000>;
	};
};

&ddr_dfs {
	  sprd-scene = "boost", "lcdon", "lcdoff", "camlow",
			"camhigh", "camveryhigh", "faceid", "top", "boot-opt";
	  sprd-freq = <1333 768 256 1333 1333 0xbacd 1333 0xbacd 0xbacd>;
};

&pin_controller {
	pinctrl-names =
	/* rfctl16 ,rfctl3, rfctl5 */
	"gpio_8", "gpio_22", "gpio_24",
	/* rfctl6, rfctl7, keyin0 */
	"gpio_25", "gpio_26", "gpio_32", "rfctl_32", "gpio_124",
	/* bt_rfctl2 */
	"gpio_175";
	pinctrl-0 = <&gpio_8>;
	pinctrl-1 = <&gpio_22>;
	pinctrl-2 = <&gpio_24>;
	pinctrl-3 = <&gpio_25>;
	pinctrl-4 = <&gpio_26>;
	pinctrl-5 = <&gpio_124>;
	pinctrl-6 = <&gpio_175>;

	gpio_8: rfctl16 {
		pins = "QOGIRL6_RFCTL16";
		function = "func4";
	};

	gpio_22: rfctl3 {
		pins = "QOGIRL6_RFCTL3";
		function = "func4";
	};

	gpio_24: rfctl5 {
		pins = "QOGIRL6_RFCTL5";
		function = "func4";
	};

	gpio_25: rfctl6 {
		pins = "QOGIRL6_RFCTL6";
		function = "func4";
	};

	gpio_26: rfctl7 {
		pins = "QOGIRL6_RFCTL7";
		function = "func4";
	};

	gpio_32: rfctl13 {
		pins = "QOGIRL6_RFCTL13";
		function = "func4";
	};

	rfctl_32: rfctl13new {
		pins = "QOGIRL6_RFCTL13";
		function = "func2";
	};

	gpio_124: keyin0 {
		pins = "QOGIRL6_KEYIN0";
		function = "func4";
	};

	gpio_175: bt_rfctl2 {
		pins = "QOGIRL6_BT_RFCTL2";
		function = "func4";
	};
};

&ion {
	#address-cells = <1>;
	#size-cells = <0>;
	heap@4 {
		reg = <4>;
		label = "carveout_fd";
		type = <2>;
		memory-region = <&fd_reserved>;
	};
};

&adi_bus {
	sprd,hw-channels = <2 0x18cc>, <3 0x18cc>, <13 0x1854>, <15 0x1874>,
			<17 0x1844>, <19 0x1844>, <21 0x1864>, <30 0x1820>,
			<32 0x197c>, <33 0x1988>, <35 0x19b8>, <39 0x19ac>;
	sprd,hw-channels0 = <2 0x18cc>, <3 0x18cc>, <13 0x1874>, <15 0x1874>,
			<17 0x1844>, <19 0x1854>, <21 0x1864>, <30 0x1820>,
			<32 0x197c>, <33 0x1988>, <35 0x19b8>, <39 0x19ac>;
	sprd,hw-channels1 = <2 0x18cc>, <3 0x18cc>, <13 0x1854>, <15 0x1874>,
			<17 0x1844>, <19 0x1844>, <21 0x1864>, <30 0x1820>,
			<32 0x197c>, <33 0x1988>, <35 0x19b8>, <39 0x19ac>;
};

/* M170 code for ext-pa by hanyifan10 at 220829 begin */
&sprd_headset {
	status = "okay";
};

&sprd_audio_codec_ana {
	status = "okay";
	hp-use-inter-pa = <1>;
	fixed-sample-rate = <48000 48000 48000>;
	digital-codec = <&sprd_audio_codec_dig>;
};

&sound_vbc_v4_sprd_codec {
	status = "okay";

	/*ext_control_type, hook selection, mode, gpio share*/
	sprd,spk-ext-pa-info = <0 0 2 0>;
	sprd,spk-ext-pa-gpio = <&ap_gpio 129 0>;
};
/* M170 code for ext-pa by hanyifan10 at 220829 end */

